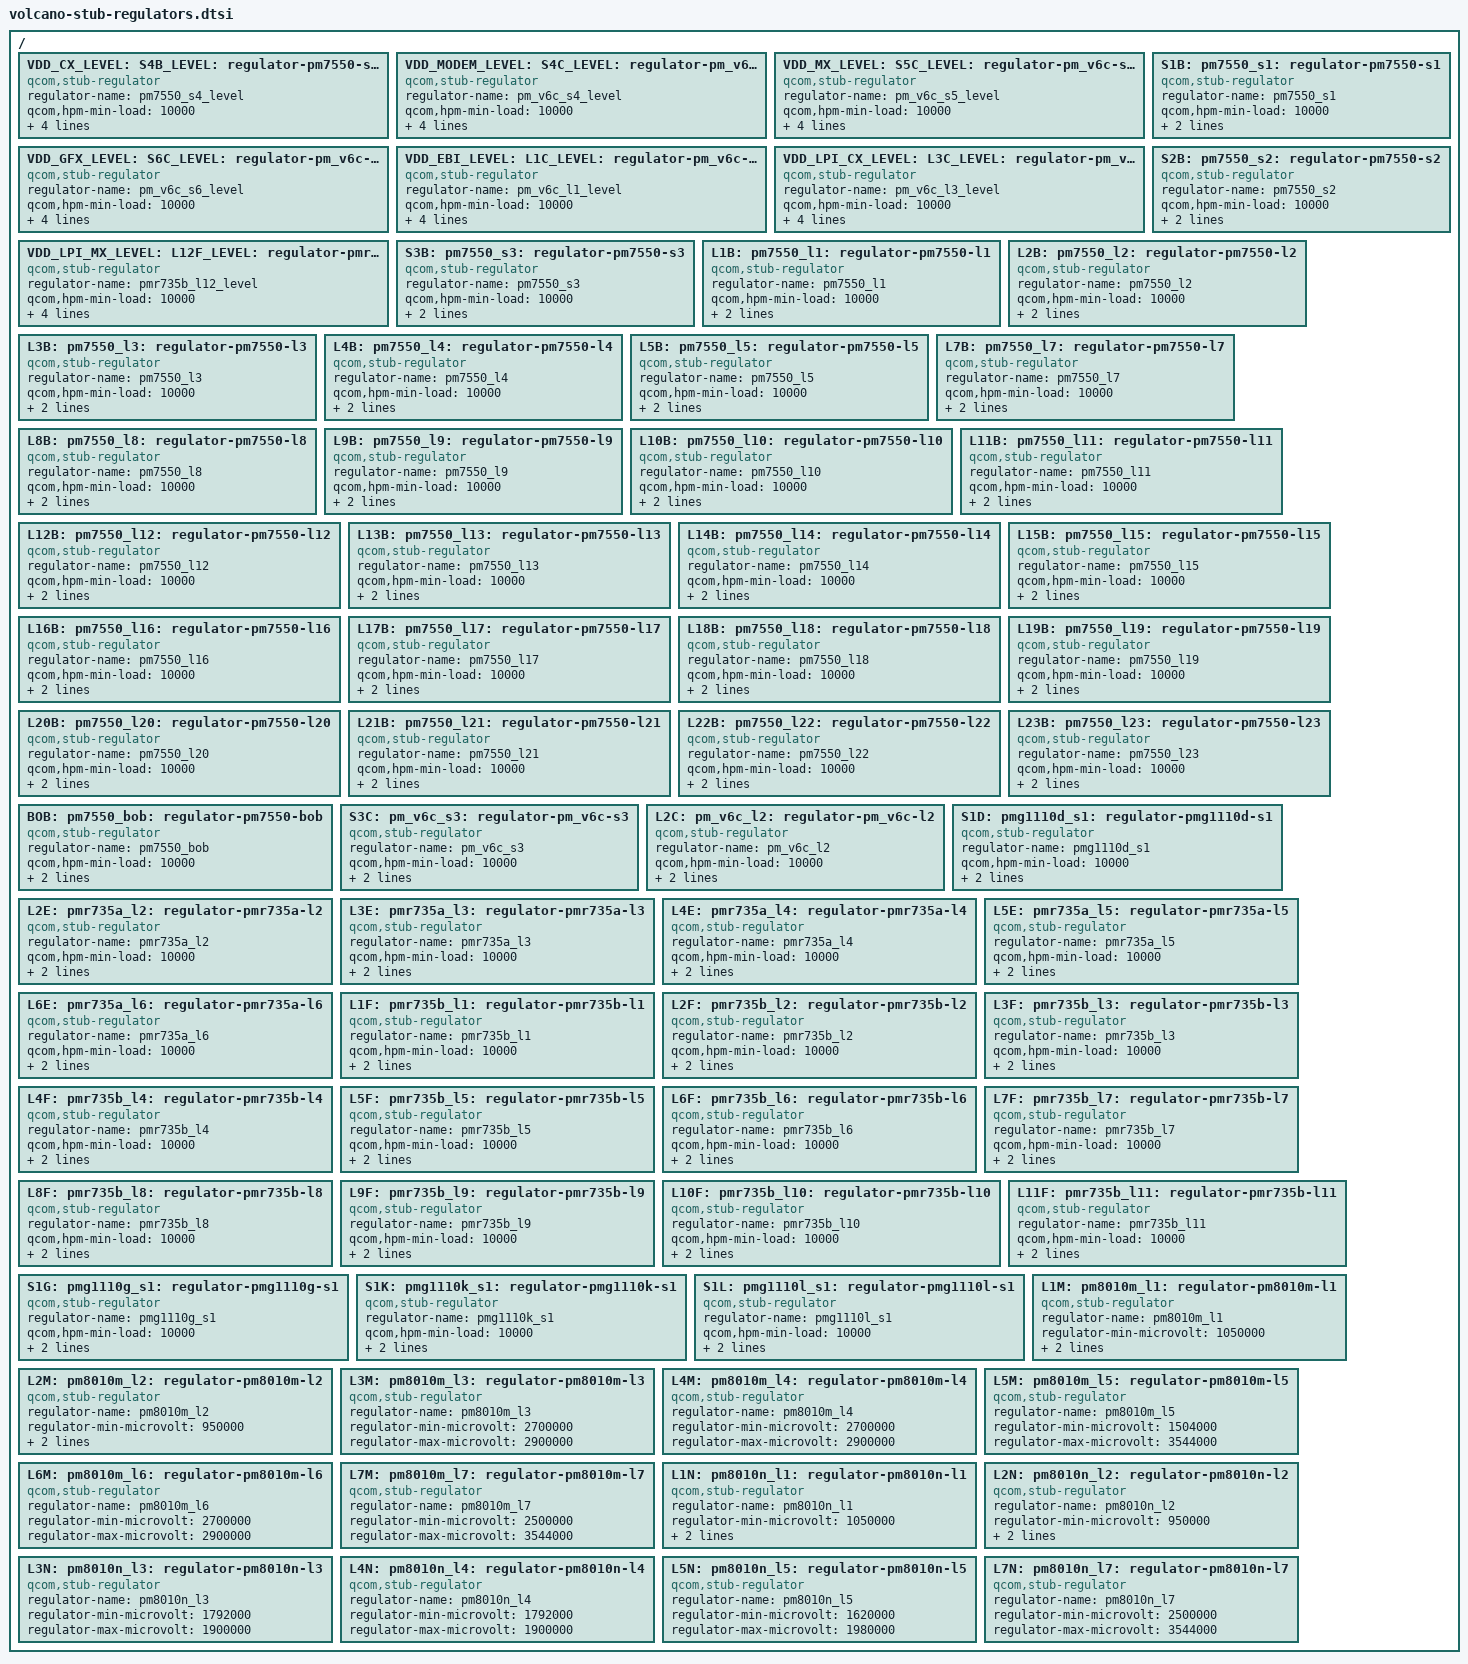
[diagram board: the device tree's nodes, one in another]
#include <dt-bindings/regulator/qcom,rpmh-regulator-levels.h>

/ {

	VDD_CX_LEVEL:
	S4B_LEVEL:
	pm7550_s4_level: regulator-pm7550-s4-level {
		compatible = "qcom,stub-regulator";
		regulator-name = "pm7550_s4_level";
		qcom,hpm-min-load = <10000>;
		regulator-min-microvolt =
			<RPMH_REGULATOR_LEVEL_RETENTION>;
		regulator-max-microvolt = <RPMH_REGULATOR_LEVEL_MAX>;
	};

	VDD_MODEM_LEVEL:
	S4C_LEVEL:
	pm_v6c_s4_level: regulator-pm_v6c-s4-level {
		compatible = "qcom,stub-regulator";
		regulator-name = "pm_v6c_s4_level";
		qcom,hpm-min-load = <10000>;
		regulator-min-microvolt =
			<RPMH_REGULATOR_LEVEL_RETENTION>;
		regulator-max-microvolt = <RPMH_REGULATOR_LEVEL_MAX>;
	};

	VDD_MX_LEVEL:
	S5C_LEVEL:
	pm_v6c_s5_level: regulator-pm_v6c-s5-level {
		compatible = "qcom,stub-regulator";
		regulator-name = "pm_v6c_s5_level";
		qcom,hpm-min-load = <10000>;
		regulator-min-microvolt =
			<RPMH_REGULATOR_LEVEL_RETENTION>;
		regulator-max-microvolt = <RPMH_REGULATOR_LEVEL_MAX>;
	};

	VDD_GFX_LEVEL:
	S6C_LEVEL:
	pm_v6c_s6_level: regulator-pm_v6c-s6-level {
		compatible = "qcom,stub-regulator";
		regulator-name = "pm_v6c_s6_level";
		qcom,hpm-min-load = <10000>;
		regulator-min-microvolt =
			<RPMH_REGULATOR_LEVEL_RETENTION>;
		regulator-max-microvolt = <RPMH_REGULATOR_LEVEL_MAX>;
	};

	VDD_EBI_LEVEL:
	L1C_LEVEL:
	pm_v6c_l1_level: regulator-pm_v6c-l1-level {
		compatible = "qcom,stub-regulator";
		regulator-name = "pm_v6c_l1_level";
		qcom,hpm-min-load = <10000>;
		regulator-min-microvolt =
			<RPMH_REGULATOR_LEVEL_RETENTION>;
		regulator-max-microvolt = <RPMH_REGULATOR_LEVEL_MAX>;
	};

	VDD_LPI_CX_LEVEL:
	L3C_LEVEL:
	pm_v6c_l3_level: regulator-pm_v6c-l3-level {
		compatible = "qcom,stub-regulator";
		regulator-name = "pm_v6c_l3_level";
		qcom,hpm-min-load = <10000>;
		regulator-min-microvolt =
			<RPMH_REGULATOR_LEVEL_RETENTION>;
		regulator-max-microvolt = <RPMH_REGULATOR_LEVEL_MAX>;
	};

	VDD_LPI_MX_LEVEL:
	L12F_LEVEL:
	pmr735b_l12_level: regulator-pmr735b-l12-level {
		compatible = "qcom,stub-regulator";
		regulator-name = "pmr735b_l12_level";
		qcom,hpm-min-load = <10000>;
		regulator-min-microvolt =
			<RPMH_REGULATOR_LEVEL_RETENTION>;
		regulator-max-microvolt = <RPMH_REGULATOR_LEVEL_MAX>;
	};

	S1B:
	pm7550_s1: regulator-pm7550-s1 {
		compatible = "qcom,stub-regulator";
		regulator-name = "pm7550_s1";
		qcom,hpm-min-load = <10000>;
		regulator-min-microvolt = <1800000>;
		regulator-max-microvolt = <2040000>;
	};

	S2B:
	pm7550_s2: regulator-pm7550-s2 {
		compatible = "qcom,stub-regulator";
		regulator-name = "pm7550_s2";
		qcom,hpm-min-load = <10000>;
		regulator-min-microvolt = <1256000>;
		regulator-max-microvolt = <1408000>;
	};

	S3B:
	pm7550_s3: regulator-pm7550-s3 {
		compatible = "qcom,stub-regulator";
		regulator-name = "pm7550_s3";
		qcom,hpm-min-load = <10000>;
		regulator-min-microvolt = <880000>;
		regulator-max-microvolt = <1040000>;
	};

	L1B:
	pm7550_l1: regulator-pm7550-l1 {
		compatible = "qcom,stub-regulator";
		regulator-name = "pm7550_l1";
		qcom,hpm-min-load = <10000>;
		regulator-min-microvolt = <720000>;
		regulator-max-microvolt = <1050000>;
	};

	L2B:
	pm7550_l2: regulator-pm7550-l2 {
		compatible = "qcom,stub-regulator";
		regulator-name = "pm7550_l2";
		qcom,hpm-min-load = <10000>;
		regulator-min-microvolt = <880000>;
		regulator-max-microvolt = <912000>;
	};

	L3B:
	pm7550_l3: regulator-pm7550-l3 {
		compatible = "qcom,stub-regulator";
		regulator-name = "pm7550_l3";
		qcom,hpm-min-load = <10000>;
		regulator-min-microvolt = <880000>;
		regulator-max-microvolt = <912000>;
	};

	L4B:
	pm7550_l4: regulator-pm7550-l4 {
		compatible = "qcom,stub-regulator";
		regulator-name = "pm7550_l4";
		qcom,hpm-min-load = <10000>;
		regulator-min-microvolt = <1200000>;
		regulator-max-microvolt = <1200000>;
	};

	L5B:
	pm7550_l5: regulator-pm7550-l5 {
		compatible = "qcom,stub-regulator";
		regulator-name = "pm7550_l5";
		qcom,hpm-min-load = <10000>;
		regulator-min-microvolt = <1200000>;
		regulator-max-microvolt = <1200000>;
	};

	L7B:
	pm7550_l7: regulator-pm7550-l7 {
		compatible = "qcom,stub-regulator";
		regulator-name = "pm7550_l7";
		qcom,hpm-min-load = <10000>;
		regulator-min-microvolt = <1800000>;
		regulator-max-microvolt = <1800000>;
	};

	L8B:
	pm7550_l8: regulator-pm7550-l8 {
		compatible = "qcom,stub-regulator";
		regulator-name = "pm7550_l8";
		qcom,hpm-min-load = <10000>;
		regulator-min-microvolt = <1800000>;
		regulator-max-microvolt = <1800000>;
	};

	L9B:
	pm7550_l9: regulator-pm7550-l9 {
		compatible = "qcom,stub-regulator";
		regulator-name = "pm7550_l9";
		qcom,hpm-min-load = <10000>;
		regulator-min-microvolt = <1800000>;
		regulator-max-microvolt = <1800000>;
	};

	L10B:
	pm7550_l10: regulator-pm7550-l10 {
		compatible = "qcom,stub-regulator";
		regulator-name = "pm7550_l10";
		qcom,hpm-min-load = <10000>;
		regulator-min-microvolt = <1800000>;
		regulator-max-microvolt = <1800000>;
	};

	L11B:
	pm7550_l11: regulator-pm7550-l11 {
		compatible = "qcom,stub-regulator";
		regulator-name = "pm7550_l11";
		qcom,hpm-min-load = <10000>;
		regulator-min-microvolt = <1800000>;
		regulator-max-microvolt = <1800000>;
	};

	L12B:
	pm7550_l12: regulator-pm7550-l12 {
		compatible = "qcom,stub-regulator";
		regulator-name = "pm7550_l12";
		qcom,hpm-min-load = <10000>;
		regulator-min-microvolt = <2400000>;
		regulator-max-microvolt = <3300000>;
	};

	L13B:
	pm7550_l13: regulator-pm7550-l13 {
		compatible = "qcom,stub-regulator";
		regulator-name = "pm7550_l13";
		qcom,hpm-min-load = <10000>;
		regulator-min-microvolt = <2700000>;
		regulator-max-microvolt = <3300000>;
	};

	L14B:
	pm7550_l14: regulator-pm7550-l14 {
		compatible = "qcom,stub-regulator";
		regulator-name = "pm7550_l14";
		qcom,hpm-min-load = <10000>;
		regulator-min-microvolt = <3300000>;
		regulator-max-microvolt = <3300000>;
	};

	L15B:
	pm7550_l15: regulator-pm7550-l15 {
		compatible = "qcom,stub-regulator";
		regulator-name = "pm7550_l15";
		qcom,hpm-min-load = <10000>;
		regulator-min-microvolt = <3300000>;
		regulator-max-microvolt = <3300000>;
	};

	L16B:
	pm7550_l16: regulator-pm7550-l16 {
		compatible = "qcom,stub-regulator";
		regulator-name = "pm7550_l16";
		qcom,hpm-min-load = <10000>;
		regulator-min-microvolt = <3008000>;
		regulator-max-microvolt = <3008000>;
	};

	L17B:
	pm7550_l17: regulator-pm7550-l17 {
		compatible = "qcom,stub-regulator";
		regulator-name = "pm7550_l17";
		qcom,hpm-min-load = <10000>;
		regulator-min-microvolt = <3104000>;
		regulator-max-microvolt = <3104000>;
	};

	L18B:
	pm7550_l18: regulator-pm7550-l18 {
		compatible = "qcom,stub-regulator";
		regulator-name = "pm7550_l18";
		qcom,hpm-min-load = <10000>;
		regulator-min-microvolt = <2800000>;
		regulator-max-microvolt = <2800000>;
	};

	L19B:
	pm7550_l19: regulator-pm7550-l19 {
		compatible = "qcom,stub-regulator";
		regulator-name = "pm7550_l19";
		qcom,hpm-min-load = <10000>;
		regulator-min-microvolt = <3000000>;
		regulator-max-microvolt = <3000000>;
	};

	L20B:
	pm7550_l20: regulator-pm7550-l20 {
		compatible = "qcom,stub-regulator";
		regulator-name = "pm7550_l20";
		qcom,hpm-min-load = <10000>;
		regulator-min-microvolt = <1620000>;
		regulator-max-microvolt = <3544000>;
	};

	L21B:
	pm7550_l21: regulator-pm7550-l21 {
		compatible = "qcom,stub-regulator";
		regulator-name = "pm7550_l21";
		qcom,hpm-min-load = <10000>;
		regulator-min-microvolt = <1620000>;
		regulator-max-microvolt = <3544000>;
	};

	L22B:
	pm7550_l22: regulator-pm7550-l22 {
		compatible = "qcom,stub-regulator";
		regulator-name = "pm7550_l22";
		qcom,hpm-min-load = <10000>;
		regulator-min-microvolt = <3200000>;
		regulator-max-microvolt = <3200000>;
	};

	L23B:
	pm7550_l23: regulator-pm7550-l23 {
		compatible = "qcom,stub-regulator";
		regulator-name = "pm7550_l23";
		qcom,hpm-min-load = <10000>;
		regulator-min-microvolt = <1650000>;
		regulator-max-microvolt = <3544000>;
	};

	BOB:
	pm7550_bob: regulator-pm7550-bob {
		compatible = "qcom,stub-regulator";
		regulator-name = "pm7550_bob";
		qcom,hpm-min-load = <10000>;
		regulator-min-microvolt = <3008000>;
		regulator-max-microvolt = <3960000>;
	};

	S3C:
	pm_v6c_s3: regulator-pm_v6c-s3 {
		compatible = "qcom,stub-regulator";
		regulator-name = "pm_v6c_s3";
		qcom,hpm-min-load = <10000>;
		regulator-min-microvolt = <1010000>;
		regulator-max-microvolt = <1170000>;
	};

	L2C:
	pm_v6c_l2: regulator-pm_v6c-l2 {
		compatible = "qcom,stub-regulator";
		regulator-name = "pm_v6c_l2";
		qcom,hpm-min-load = <10000>;
		regulator-min-microvolt = <320000>;
		regulator-max-microvolt = <650000>;
	};

	S1D:
	pmg1110d_s1: regulator-pmg1110d-s1 {
		compatible = "qcom,stub-regulator";
		regulator-name = "pmg1110d_s1";
		qcom,hpm-min-load = <10000>;
		regulator-min-microvolt = <1010000>;
		regulator-max-microvolt = <1170000>;
	};

	L2E:
	pmr735a_l2: regulator-pmr735a-l2 {
		compatible = "qcom,stub-regulator";
		regulator-name = "pmr735a_l2";
		qcom,hpm-min-load = <10000>;
		regulator-min-microvolt = <800000>;
		regulator-max-microvolt = <800000>;
	};

	L3E:
	pmr735a_l3: regulator-pmr735a-l3 {
		compatible = "qcom,stub-regulator";
		regulator-name = "pmr735a_l3";
		qcom,hpm-min-load = <10000>;
		regulator-min-microvolt = <588000>;
		regulator-max-microvolt = <800000>;
	};

	L4E:
	pmr735a_l4: regulator-pmr735a-l4 {
		compatible = "qcom,stub-regulator";
		regulator-name = "pmr735a_l4";
		qcom,hpm-min-load = <10000>;
		regulator-min-microvolt = <1776000>;
		regulator-max-microvolt = <1776000>;
	};

	L5E:
	pmr735a_l5: regulator-pmr735a-l5 {
		compatible = "qcom,stub-regulator";
		regulator-name = "pmr735a_l5";
		qcom,hpm-min-load = <10000>;
		regulator-min-microvolt = <1200000>;
		regulator-max-microvolt = <1200000>;
	};

	L6E:
	pmr735a_l6: regulator-pmr735a-l6 {
		compatible = "qcom,stub-regulator";
		regulator-name = "pmr735a_l6";
		qcom,hpm-min-load = <10000>;
		regulator-min-microvolt = <880000>;
		regulator-max-microvolt = <912000>;
	};

	L1F:
	pmr735b_l1: regulator-pmr735b-l1 {
		compatible = "qcom,stub-regulator";
		regulator-name = "pmr735b_l1";
		qcom,hpm-min-load = <10000>;
		regulator-min-microvolt = <852000>;
		regulator-max-microvolt = <950000>;
	};

	L2F:
	pmr735b_l2: regulator-pmr735b-l2 {
		compatible = "qcom,stub-regulator";
		regulator-name = "pmr735b_l2";
		qcom,hpm-min-load = <10000>;
		regulator-min-microvolt = <751000>;
		regulator-max-microvolt = <824000>;
	};

	L3F:
	pmr735b_l3: regulator-pmr735b-l3 {
		compatible = "qcom,stub-regulator";
		regulator-name = "pmr735b_l3";
		qcom,hpm-min-load = <10000>;
		regulator-min-microvolt = <1500000>;
		regulator-max-microvolt = <1800000>;
	};

	L4F:
	pmr735b_l4: regulator-pmr735b-l4 {
		compatible = "qcom,stub-regulator";
		regulator-name = "pmr735b_l4";
		qcom,hpm-min-load = <10000>;
		regulator-min-microvolt = <1700000>;
		regulator-max-microvolt = <1950000>;
	};

	L5F:
	pmr735b_l5: regulator-pmr735b-l5 {
		compatible = "qcom,stub-regulator";
		regulator-name = "pmr735b_l5";
		qcom,hpm-min-load = <10000>;
		regulator-min-microvolt = <1140000>;
		regulator-max-microvolt = <1260000>;
	};

	L6F:
	pmr735b_l6: regulator-pmr735b-l6 {
		compatible = "qcom,stub-regulator";
		regulator-name = "pmr735b_l6";
		qcom,hpm-min-load = <10000>;
		regulator-min-microvolt = <1200000>;
		regulator-max-microvolt = <1200000>;
	};

	L7F:
	pmr735b_l7: regulator-pmr735b-l7 {
		compatible = "qcom,stub-regulator";
		regulator-name = "pmr735b_l7";
		qcom,hpm-min-load = <10000>;
		regulator-min-microvolt = <1080000>;
		regulator-max-microvolt = <1350000>;
	};

	L8F:
	pmr735b_l8: regulator-pmr735b-l8 {
		compatible = "qcom,stub-regulator";
		regulator-name = "pmr735b_l8";
		qcom,hpm-min-load = <10000>;
		regulator-min-microvolt = <1100000>;
		regulator-max-microvolt = <1320000>;
	};

	L9F:
	pmr735b_l9: regulator-pmr735b-l9 {
		compatible = "qcom,stub-regulator";
		regulator-name = "pmr735b_l9";
		qcom,hpm-min-load = <10000>;
		regulator-min-microvolt = <870000>;
		regulator-max-microvolt = <970000>;
	};

	L10F:
	pmr735b_l10: regulator-pmr735b-l10 {
		compatible = "qcom,stub-regulator";
		regulator-name = "pmr735b_l10";
		qcom,hpm-min-load = <10000>;
		regulator-min-microvolt = <1800000>;
		regulator-max-microvolt = <1800000>;
	};

	L11F:
	pmr735b_l11: regulator-pmr735b-l11 {
		compatible = "qcom,stub-regulator";
		regulator-name = "pmr735b_l11";
		qcom,hpm-min-load = <10000>;
		regulator-min-microvolt = <320000>;
		regulator-max-microvolt = <864000>;
	};

	S1G:
	pmg1110g_s1: regulator-pmg1110g-s1 {
		compatible = "qcom,stub-regulator";
		regulator-name = "pmg1110g_s1";
		qcom,hpm-min-load = <10000>;
		regulator-min-microvolt = <1010000>;
		regulator-max-microvolt = <1170000>;
	};

	S1K:
	pmg1110k_s1: regulator-pmg1110k-s1 {
		compatible = "qcom,stub-regulator";
		regulator-name = "pmg1110k_s1";
		qcom,hpm-min-load = <10000>;
		regulator-min-microvolt = <300000>;
		regulator-max-microvolt = <1004000>;
	};

	S1L:
	pmg1110l_s1: regulator-pmg1110l-s1 {
		compatible = "qcom,stub-regulator";
		regulator-name = "pmg1110l_s1";
		qcom,hpm-min-load = <10000>;
		regulator-min-microvolt = <300000>;
		regulator-max-microvolt = <1004000>;
	};

	L1M: pm8010m_l1: regulator-pm8010m-l1 {
		compatible = "qcom,stub-regulator";
		regulator-name = "pm8010m_l1";
		regulator-min-microvolt = <1050000>;
		regulator-max-microvolt = <1180000>;
		qcom,hpm-min-load = <30000>;
	};

	L2M: pm8010m_l2: regulator-pm8010m-l2 {
		compatible = "qcom,stub-regulator";
		regulator-name = "pm8010m_l2";
		regulator-min-microvolt = <950000>;
		regulator-max-microvolt = <1150000>;
		qcom,hpm-min-load = <30000>;
	};

	L3M: pm8010m_l3: regulator-pm8010m-l3 {
		compatible = "qcom,stub-regulator";
		regulator-name = "pm8010m_l3";
		regulator-min-microvolt = <2700000>;
		regulator-max-microvolt = <2900000>;
	};

	L4M: pm8010m_l4: regulator-pm8010m-l4 {
		compatible = "qcom,stub-regulator";
		regulator-name = "pm8010m_l4";
		regulator-min-microvolt = <2700000>;
		regulator-max-microvolt = <2900000>;
	};

	L5M: pm8010m_l5: regulator-pm8010m-l5 {
		compatible = "qcom,stub-regulator";
		regulator-name = "pm8010m_l5";
		regulator-min-microvolt = <1504000>;
		regulator-max-microvolt = <3544000>;
	};

	L6M: pm8010m_l6: regulator-pm8010m-l6 {
		compatible = "qcom,stub-regulator";
		regulator-name = "pm8010m_l6";
		regulator-min-microvolt = <2700000>;
		regulator-max-microvolt = <2900000>;
	};

	L7M: pm8010m_l7: regulator-pm8010m-l7 {
		compatible = "qcom,stub-regulator";
		regulator-name = "pm8010m_l7";
		regulator-min-microvolt = <2500000>;
		regulator-max-microvolt = <3544000>;
	};

	L1N: pm8010n_l1: regulator-pm8010n-l1 {
		compatible = "qcom,stub-regulator";
		regulator-name = "pm8010n_l1";
		regulator-min-microvolt = <1050000>;
		regulator-max-microvolt = <1200000>;
		qcom,hpm-min-load = <30000>;
	};

	L2N: pm8010n_l2: regulator-pm8010n-l2 {
		compatible = "qcom,stub-regulator";
		regulator-name = "pm8010n_l2";
		regulator-min-microvolt = <950000>;
		regulator-max-microvolt = <1150000>;
		qcom,hpm-min-load = <30000>;
	};

	L3N: pm8010n_l3: regulator-pm8010n-l3 {
		compatible = "qcom,stub-regulator";
		regulator-name = "pm8010n_l3";
		regulator-min-microvolt = <1792000>;
		regulator-max-microvolt = <1900000>;
	};

	L4N: pm8010n_l4: regulator-pm8010n-l4 {
		compatible = "qcom,stub-regulator";
		regulator-name = "pm8010n_l4";
		regulator-min-microvolt = <1792000>;
		regulator-max-microvolt = <1900000>;
	};

	L5N: pm8010n_l5: regulator-pm8010n-l5 {
		compatible = "qcom,stub-regulator";
		regulator-name = "pm8010n_l5";
		regulator-min-microvolt = <1620000>;
		regulator-max-microvolt = <1980000>;
	};

	L7N: pm8010n_l7: regulator-pm8010n-l7 {
		compatible = "qcom,stub-regulator";
		regulator-name = "pm8010n_l7";
		regulator-min-microvolt = <2500000>;
		regulator-max-microvolt = <3544000>;
	};
};
